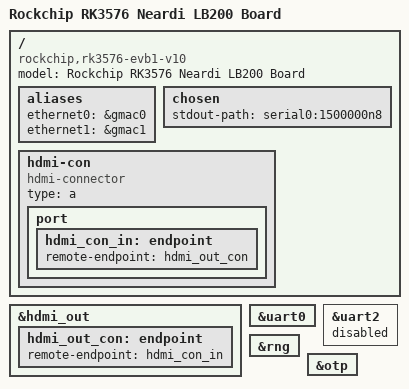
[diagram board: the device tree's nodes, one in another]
// SPDX-License-Identifier: (GPL-2.0+ OR MIT)
/*
 * Copyright (c) 2024 Neardi Inc.
 * Copyright (c) 2024 Rockchip Electronics Co., Ltd.
 *
 * Neardi RK3576 LB200 Board - mainline kernel 6.18+
 */

/dts-v1/;

#include <dt-bindings/gpio/gpio.h>
#include <dt-bindings/input/input.h>
#include <dt-bindings/usb/pd.h>
#include <dt-bindings/pinctrl/rockchip.h>
#include <dt-bindings/soc/rockchip,vop2.h>
#include "rk3576.dtsi"
#include "rk3576-rk806.dtsi"
#include "rk3576-neardi-lb200.dtsi"
#include "rk3576-neardi-lb200-gmac.dtsi"
#include "rk3576-neardi-lb200-hdmi.dtsi"
#include "rk3576-neardi-lb200-full-typec-phy.dtsi"
#include "rk3576-neardi-lb200-dp.dtsi"
#include "rk3576-neardi-lb200-wifibt.dtsi"
#include "rk3576-neardi-lb200-misc-devices.dtsi"
#include "rk3576-neardi-lb200-sound-ctl.dtsi"
#include "rk3576-neardi-lb200-input-keymap.dtsi"

/ {
	model = "Rockchip RK3576 Neardi LB200 Board";
	compatible = "rockchip,rk3576-evb1-v10", "rockchip,rk3576", "neardi,rk3576-lb200";

	aliases {
		ethernet0 = &gmac0;
		ethernet1 = &gmac1;
	};

	chosen {
		/* Vendor firmware debug port is UART0 ("Preloader serial: 0") */
		stdout-path = "serial0:1500000n8";
	};

	hdmi-con {
		compatible = "hdmi-connector";
		type = "a";

		port {
			hdmi_con_in: endpoint {
				remote-endpoint = <&hdmi_out_con>;
			};
		};
	};
};

&hdmi_out {
	hdmi_out_con: endpoint {
		remote-endpoint = <&hdmi_con_in>;
	};
};

/* Debug console; pins already muxed by the vendor SPL, don't remux */
&uart0 {
	status = "okay";
	/delete-property/ pinctrl-names;
	/delete-property/ pinctrl-0;
};

/* Console is UART0; UART2 pins conflict with SPI flash (sfc1 / fspi1m1) */
&uart2 {
	status = "disabled";
};

&rng {
	status = "okay";
};

&otp {
	status = "okay";
};
